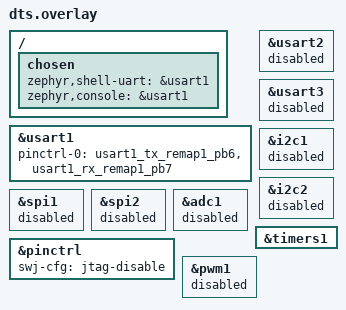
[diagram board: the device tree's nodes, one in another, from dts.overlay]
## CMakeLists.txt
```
# SPDX-License-Identifier: GPL-2.0-or-later
cmake_minimum_required(VERSION 3.20.1)
set(BOARD stm32_min_dev_blue)
set(DTC_OVERLAY_FILE dts.overlay)
find_package(Zephyr REQUIRED)
project(keypecker VERSION 1)
target_sources(
	app PRIVATE
	src/kp.c
	src/kp_shell.c
	src/kp_input.c
	src/kp_act.c
	src/kp_cap.c
	src/kp_sample.c
	src/kp_meas.c
	src/kp_table.c
)
```

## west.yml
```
# SPDX-License-Identifier: GPL-2.0-or-later
manifest:
  self:
    path: keypecker

  remotes:
    - name: zephyrproject-rtos
      url-base: https://github.com/zephyrproject-rtos

  projects:
    - name: zephyr
      remote: zephyrproject-rtos
      revision: main
      import: true
```

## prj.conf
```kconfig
CONFIG_ASSERT=y

CONFIG_FLASH_SIZE=128
CONFIG_PRINTK=y
CONFIG_SHELL=y
CONFIG_SHELL_HELP=y
CONFIG_SHELL_STACK_SIZE=2048
CONFIG_SHELL_BACKEND_SERIAL=y
CONFIG_SHELL_PROMPT_UART="keypecker:~$ "

CONFIG_HWINFO_SHELL=n

CONFIG_THREAD_MONITOR=y
CONFIG_INIT_STACKS=y
CONFIG_BOOT_BANNER=y
CONFIG_THREAD_NAME=y
CONFIG_LOG=y
CONFIG_LOG_MODE_MINIMAL=y
CONFIG_CBPRINTF_NANO=y
```

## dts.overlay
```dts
/*
 * Copyright (c) 2021 Nordic Semiconductor ASA
 *
 * SPDX-License-Identifier: Apache-2.0
 */

/ {
	chosen {
		zephyr,shell-uart = &usart1;
		zephyr,console = &usart1;
	};
};

&usart1 {
	status = "okay";
	pinctrl-0 = < &usart1_tx_remap1_pb6 &usart1_rx_remap1_pb7 >;
};
&usart2 {
	status = "disabled";
};
&usart3 {
	status = "disabled";
};
&i2c1 {
	status = "disabled";
};
&i2c2 {
	status = "disabled";
};
&spi1 {
	status = "disabled";
};
&spi2 {
	status = "disabled";
};
&adc1 {
	status = "disabled";
};
&pinctrl {
	swj-cfg = "jtag-disable";
};

&timers1 {
	status = "okay";
};

&pwm1 {
	status = "disabled";
};
```

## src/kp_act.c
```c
/** @file
 *  @brief Keypecker actuator
 */

/*
 * Copyright (c) 2022 Nikolai Kondrashov
 *
 * SPDX-License-Identifier: GPL-2.0-or-later
 */

#include "kp_act.h"

/*
 * Only changed upon initialization.
 */

/** The GPIO port device */
static const struct device * volatile kp_act_gpio = NULL;

/** The "disable" output GPIO pin */
static gpio_pin_t kp_act_gpio_pin_disable;

/** The "dir" output GPIO pin */
static gpio_pin_t kp_act_gpio_pin_dir;

/** The "step" output GPIO pin */
static gpio_pin_t kp_act_gpio_pin_step;

/*
 * General state changed by all functions
 */
/** The spinlock protecting the base state */
static struct k_spinlock kp_act_lock = {};

/** Execute the following statement with base state lock held */
#define KP_ACT_WITH_LOCK \
	for (k_spinlock_key_t _key = k_spin_lock(&kp_act_lock), \
			      _i = {0}; \
	     _i.key == 0; \
	     k_spin_unlock(&kp_act_lock, _key), _i.key = 1)

/** The current actuator position, in steps */
static volatile int32_t kp_act_pos;

/** True if a move has to be aborted, false otherwise */
static volatile bool kp_act_move_aborted;

/*
 * Movement state accessed by move.../locate functions
 */

/** The semaphore signaling a movement can be started */
static K_SEM_DEFINE(kp_act_move_available, 1, 1);

/** The semaphore signaling a movement should begin */
static K_SEM_DEFINE(kp_act_move_begin, 0, 1);

/** The move target position, in steps */
static int32_t kp_act_target;

/** The timestamp of the last step in cycles */
static uint32_t kp_act_move_last_cycles;

/** True if the last step was in the positive direction, false otherwise */
static bool kp_act_move_last_positive;

/** The semaphore signaling a movement is done */
static K_SEM_DEFINE(kp_act_move_done, 0, 1);

/** The move result, only valid when kp_act_move_done is available */
static volatile enum kp_act_move_rc kp_act_move_rc;

/*
 * End of state
 */

/**
 * Check if the actuator power is off, assuming the state mutex is held.
 *
 * @return True if the power is off, false if on.
 */
static inline bool
kp_act_is_off_locked(void)
{
	return gpio_pin_get(kp_act_gpio, kp_act_gpio_pin_disable);
}

/**
 * Check if the actuator power is on, assuming the state mutex is held.
 *
 * @return True if the power is on, false if off.
 */
static inline bool
kp_act_is_on_locked(void)
{
	return !kp_act_is_off_locked();
}

bool
kp_act_is_off(void)
{
	bool is_off;
	assert(kp_act_is_initialized());
	KP_ACT_WITH_LOCK {
		is_off = kp_act_is_off_locked();
	}
	return is_off;
}

bool
kp_act_on(void)
{
	bool turned_on = false;
	assert(kp_act_is_initialized());
	KP_ACT_WITH_LOCK {
		if (kp_act_is_off_locked()) {
			gpio_pin_set(kp_act_gpio, kp_act_gpio_pin_disable, 0);
			turned_on = true;
		}
	}
	return turned_on;
}

bool
kp_act_off(void)
{
	bool turned_off = false;
	assert(kp_act_is_initialized());
	KP_ACT_WITH_LOCK {
		/* If we're moving, the move aborts with KP_ACT_MOVE_RC_OFF */
		if (kp_act_is_on_locked()) {
			gpio_pin_set(kp_act_gpio, kp_act_gpio_pin_disable, 1);
			kp_act_pos = 0;
			turned_off = true;
		}
	}
	return turned_off;
}

int32_t
kp_act_locate(void)
{
	int32_t pos;
	assert(kp_act_is_initialized());
	KP_ACT_WITH_LOCK {
		pos = kp_act_is_on_locked()
			? kp_act_pos
			: KP_ACT_POS_INVALID;
	}
	return pos;
}

/** Move timer */
static K_TIMER_DEFINE(kp_act_move_timer, NULL, NULL);

/** Minimum move timer period, us */
#define KP_ACT_MOVE_TIMER_PERIOD_MIN_US	400

/** Maximum move timer period, us */
#define KP_ACT_MOVE_TIMER_PERIOD_MAX_US	4000

/**
 * Wait for next timer tick, or go to a label if timer is stopped.
 *
 * @param _stop_label	The label to go to if timer is stopped.
 */
#define KP_ACT_MOVE_TIMER_SYNC(_stop_label) \
	do {                                                    \
		/* If the timer is stopped or not started */    \
		if (!k_timer_status_sync(&kp_act_move_timer)) { \
			goto _stop_label;                       \
		}                                               \
	} while (0)

void
kp_act_move_thread_fn(void *arg1, void *arg2, void *arg3)
{
	bool positive = false;
	assert(kp_act_is_initialized());

	/* While we can get the "begin" semaphore */
	while (k_sem_take(&kp_act_move_begin, K_FOREVER) == 0) {
		/* Run the timer */
		while (true) {
			/* Control */
			KP_ACT_MOVE_TIMER_SYNC(stop);
			KP_ACT_WITH_LOCK {
				if (kp_act_is_off_locked()) {
					kp_act_move_rc = KP_ACT_MOVE_RC_OFF;
					k_timer_stop(&kp_act_move_timer);
					continue;
				}
				if (kp_act_move_aborted) {
					kp_act_move_rc =
						KP_ACT_MOVE_RC_ABORTED;
					k_timer_stop(&kp_act_move_timer);
					continue;
				}
				if (kp_act_target == kp_act_pos) {
					kp_act_move_rc = KP_ACT_MOVE_RC_OK;
					k_timer_stop(&kp_act_move_timer);
					continue;
				}
				positive = kp_act_target > kp_act_pos;
				gpio_pin_set(kp_act_gpio, kp_act_gpio_pin_dir,
					     !positive);
			}
			/* Raise */
			KP_ACT_MOVE_TIMER_SYNC(stop);
			gpio_pin_set(kp_act_gpio, kp_act_gpio_pin_step, 1);
			kp_act_move_last_cycles = k_cycle_get_32();
			kp_act_move_last_positive = positive;
			/* Hold */
			KP_ACT_MOVE_TIMER_SYNC(stop);
			KP_ACT_WITH_LOCK {
				if (positive) {
					kp_act_pos++;
				} else {
					kp_act_pos--;
				}
			}
			/* Fall */
			KP_ACT_MOVE_TIMER_SYNC(stop);
			gpio_pin_set(kp_act_gpio, kp_act_gpio_pin_step, 0);
		}
stop:;
		k_sem_give(&kp_act_move_done);
	}
}

#undef KP_ACT_MOVE_TIMER_SYNC

/** The thread moving the actuator */
K_THREAD_DEFINE(kp_act_move_thread, 512,
		kp_act_move_thread_fn, NULL, NULL, NULL,
		-1, 0, -1);

void
kp_act_start_move(bool relative, int32_t steps, uint32_t speed)
{
	bool started = false;
	uint32_t period_us;
	k_timeout_t delay = K_NO_WAIT;
	assert(relative || kp_act_pos_is_valid(steps));
	assert(speed <= 100);
	assert(kp_act_is_initialized());

	/* Wait for a move to be available */
	k_sem_take(&kp_act_move_available, K_FOREVER);

	/* Start the timer */
	KP_ACT_WITH_LOCK {
		/* If we have the power off */
		if (kp_act_is_off_locked()) {
			kp_act_move_rc = KP_ACT_MOVE_RC_OFF;
			continue;
		}
		/* Calculate target steps */
		kp_act_target =
			relative ? kp_act_pos + steps : steps;
		/* If we don't have to move */
		if (kp_act_target == kp_act_pos) {
			kp_act_move_rc = KP_ACT_MOVE_RC_OK;
			continue;
		}

		kp_act_move_aborted = false;

		/* If our direction is different from the last step */
		if ((kp_act_target > kp_act_pos) !=
				kp_act_move_last_positive) {
			/*
			 * Minimum turn delay, microseconds.
			 * The faster we move, the more time we need to absorb
			 * the momentum.
			 */
			uint32_t turn_delay_us =
				(KP_ACT_MOVE_TIMER_PERIOD_MIN_US +
				 ((KP_ACT_MOVE_TIMER_PERIOD_MAX_US -
				   KP_ACT_MOVE_TIMER_PERIOD_MIN_US) *
				  speed) / 100) * 2;
			/* Current time, cycles */
			uint32_t now_cycles = k_cycle_get_32();
			/* Microseconds from the last step */
			uint32_t elapsed_us = k_cyc_to_us_floor32(
				now_cycles > kp_act_move_last_cycles
					? now_cycles - kp_act_move_last_cycles
					/* Just always wait on overflow */
					: 0
			);
			if (elapsed_us < turn_delay_us) {
				/* Wait to absorb momentum before turning */
				delay = K_USEC(turn_delay_us - elapsed_us);
			}
		}

		/* Shorter period for faster movement */
		period_us = KP_ACT_MOVE_TIMER_PERIOD_MAX_US -
			((KP_ACT_MOVE_TIMER_PERIOD_MAX_US -
			  KP_ACT_MOVE_TIMER_PERIOD_MIN_US) *
			 speed) / 100;

		k_timer_start(&kp_act_move_timer, delay, K_USEC(period_us));
		started = true;
	}

	if (started) {
		/* Begin the move */
		k_sem_give(&kp_act_move_begin);
	} else {
		/* Complete the move */
		k_sem_give(&kp_act_move_done);
	}
}

void
kp_act_finish_move_event_init(struct k_poll_event *event)
{
	assert(kp_act_is_initialized());
	k_poll_event_init(event, K_POLL_TYPE_SEM_AVAILABLE,
			  K_POLL_MODE_NOTIFY_ONLY, &kp_act_move_done);
}

enum kp_act_move_rc
kp_act_finish_move(k_timeout_t timeout)
{
	enum kp_act_move_rc rc;
	assert(kp_act_is_initialized());

	/* Wait for the move to finish */
	if (k_sem_take(&kp_act_move_done, timeout)) {
		return KP_ACT_MOVE_TIMEOUT;
	}

	/* Remember the result */
	rc = kp_act_move_rc;

	/* Mark next move as available */
	k_sem_give(&kp_act_move_available);

	/* Return the remembered result */
	return rc;
}

bool
kp_act_abort(void)
{
	bool aborted = false;
	assert(kp_act_is_initialized());
	KP_ACT_WITH_LOCK {
		if (kp_act_is_off_locked()) {
			continue;
		}
		kp_act_move_aborted = true;
		aborted = true;
	}
	return aborted;
}

bool
kp_act_is_initialized(void)
{
	return kp_act_gpio != NULL;
}

void
kp_act_init(const struct device *gpio,
		gpio_pin_t disable_pin,
		gpio_pin_t dir_pin,
		gpio_pin_t step_pin)
{
	assert(gpio != NULL);
	assert(device_is_ready(gpio));
	assert(!kp_act_is_initialized());

	/* Move state */
	kp_act_target = 0;
	kp_act_move_last_cycles = 0;
	kp_act_move_last_positive = false;

	/* General state */
	kp_act_pos = 0;
	kp_act_move_aborted = false;

	/* Init state */
	kp_act_gpio_pin_disable = disable_pin;
	kp_act_gpio_pin_dir = dir_pin;
	kp_act_gpio_pin_step = step_pin;
	gpio_pin_configure(gpio, kp_act_gpio_pin_disable,
				GPIO_OPEN_DRAIN | GPIO_OUTPUT_HIGH);
	gpio_pin_configure(gpio, kp_act_gpio_pin_dir,
				GPIO_PUSH_PULL | GPIO_OUTPUT_LOW);
	gpio_pin_configure(gpio, kp_act_gpio_pin_step,
				GPIO_PUSH_PULL | GPIO_OUTPUT_LOW);

	/* Mark actuator initialized */
	kp_act_gpio = gpio;

	/* Start the actuator-moving thread */
	k_thread_start(kp_act_move_thread);

	assert(kp_act_is_initialized());
}
```

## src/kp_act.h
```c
/** @file
 *  @brief Keypecker actuator
 */

/*
 * Copyright (c) 2022 Nikolai Kondrashov
 *
 * SPDX-License-Identifier: GPL-2.0-or-later
 */

#ifndef KP_ACT_H_
#define KP_ACT_H_

#include <zephyr/drivers/gpio.h>
#include <zephyr/kernel.h>
#include <stdbool.h>
#include <assert.h>

#ifdef __cplusplus
extern "C" {
#endif

/**
 * Initialize the actuator to a powered-off state.
 *
 * @param gpio		The device for the GPIO port to use to control the
 *			actuator.
 * @param disable_pin	The disable pin number on the GPIO port.
 * @param dir_pin	The dir pin number on the GPIO port.
 * @param step_pin	The step pin number on the GPIO port.
 */
extern void kp_act_init(const struct device *gpio,
			gpio_pin_t disable_pin,
			gpio_pin_t dir_pin,
			gpio_pin_t step_pin);

/**
 * Check if the actuator is initialized.
 *
 * @return True if the actuator is initialized, false if not.
 */
extern bool kp_act_is_initialized(void);

/**
 * Check if the actuator power is off.
 *
 * @return True if the power is off, false if on.
 */
extern bool kp_act_is_off(void);

/**
 * Check if the actuator power is on.
 *
 * @return True if the power is on, false if off.
 */
static inline bool
kp_act_is_on(void)
{
	assert(kp_act_is_initialized());
	return !kp_act_is_off();
}

/**
 * Turn the actuator power on, if not on already.
 *
 * @return True if the power was turned on, false if it was already on.
 */
extern bool kp_act_on(void);

/**
 * Turn the actuator power off.
 *
 * @return True if the power turned off, false if it was already off.
 */
extern bool kp_act_off(void);

/** Invalid (unavailable) actuator position */
#define KP_ACT_POS_INVALID	INT32_MIN

/** Minimum possible actuator position */
#define KP_ACT_POS_MIN		(INT32_MIN + 1)

/** Maximum possible actuator position */
#define KP_ACT_POS_MAX		INT32_MAX

/**
 * Check if a position is valid.
 *
 * @param pos	The position to check.
 *
 * @return True if the position is valid, false otherwise.
 */
static inline bool kp_act_pos_is_valid(int32_t pos)
{
	return pos != KP_ACT_POS_INVALID;
}

/**
 * Retrieve the absolute position of a powered actuator.
 *
 * @return The position, if successful, or KP_ACT_POS_INVALID, if the actuator
 * 	   is powered off.
 */
extern int32_t kp_act_locate(void);

/** Result code of a movement attempt */
enum kp_act_move_rc {
	/** Move succeeded / finished */
	KP_ACT_MOVE_RC_OK,
	/** Move is aborted */
	KP_ACT_MOVE_RC_ABORTED,
	/** Actuator is off (power is invalid) */
	KP_ACT_MOVE_RC_OFF,
	/** Waiting for a move to finish timed out */
	KP_ACT_MOVE_TIMEOUT,
};

/**
 * Start moving the actuator.
 *
 * @param relative	True if the move is relative, false if absolute.
 * @param steps		The number of steps to move by, if "relative" is true.
 * 			The absolute position, in steps, if "relative" is
 * 			false. Positive - lower, negative - higher.
 * @param speed		The speed with which to move, 0-100%.
 */
extern void kp_act_start_move(bool relative, int32_t steps, uint32_t speed);

/**
 * Finish moving the actuator.
 *
 * @param timeout	The time to wait for the move to finish, or one of
 * 			the special values K_NO_WAIT and K_FOREVER.
 *
 * @return The move result code.
 */
extern enum kp_act_move_rc kp_act_finish_move(k_timeout_t timeout);

/**
 * Initialize a poll event to wait for finished actuator moves.
 *
 * @param event	The poll event to initialize.
 */
extern void kp_act_finish_move_event_init(struct k_poll_event *event);

/**
 * Move the actuator.
 *
 * @param relative	True if the move is relative, false if absolute.
 * @param steps		The number of steps to move by, if "relative" is true.
 * 			The absolute position, in steps, if "relative" is
 * 			false. Positive - lower, negative - higher.
 * @param speed		The speed with which to move, 0-100%.
 *
 * @return The move result code.
 */
static inline enum kp_act_move_rc kp_act_move(bool relative,
					      int32_t steps,
					      uint32_t speed)
{
	assert(relative || kp_act_pos_is_valid(steps));
	assert(speed <= 100);
	assert(kp_act_is_initialized());
	kp_act_start_move(relative, steps, speed);
	return kp_act_finish_move(K_FOREVER);
}

/**
 * Move the actuator to an absolute position.
 * Waits for the previous move to be finished/aborted.
 *
 * @param pos	The absolute position to move the actuator to (must be valid).
 * @param speed	The speed with which to move, 0-100%.
 *
 * @return The movement result.
 */
static inline enum kp_act_move_rc
kp_act_move_to(int32_t pos, uint32_t speed)
{
	assert(kp_act_pos_is_valid(pos));
	assert(speed <= 100);
	assert(kp_act_is_initialized());
	return kp_act_move(false, pos, speed);
}

/**
 * Start moving the actuator to an absolute position.
 * Waits for the previous move to be finished/aborted.
 *
 * @param pos	The absolute position to move the actuator to (must be valid).
 * @param speed	The speed with which to move, 0-100%.
 */
static inline void
kp_act_start_move_to(int32_t pos, uint32_t speed)
{
	assert(kp_act_pos_is_valid(pos));
	assert(speed <= 100);
	assert(kp_act_is_initialized());
	kp_act_start_move(false, pos, speed);
}

/**
 * Move the actuator by a specified number of steps.
 *
 * @param steps	The number of steps to move by: positive values
 * 		- lower, negative - higher.
 * @param speed	The speed with which to move, 0-100%.
 *
 * @return The movement result.
 */
static inline enum kp_act_move_rc
kp_act_move_by(int32_t steps, uint32_t speed)
{
	assert(speed <= 100);
	assert(kp_act_is_initialized());
	return kp_act_move(true, steps, speed);
}

/**
 * Start moving the actuator by a specified number of steps.
 *
 * @param steps	The number of steps to move by: positive values
 * 		- lower, negative - higher.
 * @param speed	The speed with which to move, 0-100%.
 *
 * @return The movement result.
 */
static inline void
kp_act_start_move_by(int32_t steps, uint32_t speed)
{
	assert(speed <= 100);
	assert(kp_act_is_initialized());
	kp_act_start_move(true, steps, speed);
}

/**
 * Abort the actuator's movement in progress, if any.
 *
 * @return True if there was no movement or it was aborted,
 * 	   false if the actuator was not powered.
 */
extern bool kp_act_abort(void);

#ifdef __cplusplus
}
#endif

#endif /* KP_ACT_H_ */
```

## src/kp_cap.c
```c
/** @file
 *  @brief Keypecker capturer
 */

/*
 * Copyright (c) 2022 Nikolai Kondrashov
 *
 * SPDX-License-Identifier: GPL-2.0-or-later
 */

#include "kp_cap.h"
#include "kp_misc.h"
#include <string.h>

/** Masks for the channels available for capture */
static const uint32_t kp_cap_ch_mask_list[KP_CAP_CH_NUM] = {
	LL_TIM_CHANNEL_CH2,
	LL_TIM_CHANNEL_CH3,
};

/** Capture interrupt-enabling/interrupt-flag masks for each channel */
/* NOTE: Assuming SR bits match DIER bits */
static const uint32_t kp_cap_ch_ccif_mask_list[KP_CAP_CH_NUM] = {
	TIM_SR_CC2IF,
	TIM_SR_CC3IF,
};

/** Overcapture flag masks for each channel */
static const uint32_t kp_cap_ch_ccof_mask_list[KP_CAP_CH_NUM] = {
	TIM_SR_CC2OF,
	TIM_SR_CC3OF,
};

/** Offset of the captured-value register for each channel, bytes */
static const size_t kp_cap_ch_ccr_offset_list[KP_CAP_CH_NUM] = {
	offsetof(TIM_TypeDef, CCR2),
	offsetof(TIM_TypeDef, CCR3),
};

/** The timer to use for capture */
static TIM_TypeDef* kp_cap_timer = NULL;

/** Debugg output configuration */
struct kp_cap_dbg_conf kp_cap_dbg_conf;

/** The semaphore signaling a capture can be started */
static K_SEM_DEFINE(kp_cap_available, 1, 1);

/** The capture interrupt mask for all channels to be captured */
static uint32_t kp_cap_ch_ccif_mask;

/** The maximum number of ticks to await capture of all channels */
static uint32_t kp_cap_timeout_ticks;

/** The minimum number of ticks to wait for a channel to bounce */
static uint32_t kp_cap_bounce_ticks;

/** The capture abort flag */
static volatile bool kp_cap_aborted;

/** The semaphore signaling a capture is done */
static K_SEM_DEFINE(kp_cap_done, 0, 1);

/** The interrupt state spinlock */
/** Only needs to be held if kp_cap_available is taken */
static struct k_spinlock kp_cap_lock = {};

void
kp_cap_isr(void *arg)
{
	static const struct kp_cap_dbg_conf *dbg = &kp_cap_dbg_conf;
	bool done = false;
	k_spinlock_key_t key;
	size_t i;

	assert(kp_cap_is_initialized());

	key = k_spin_lock(&kp_cap_lock);

	/* If the capture is not aborted */
	if (!kp_cap_aborted) {
		uint32_t sr = kp_cap_timer->SR;
		uint32_t masked_sr = sr & kp_cap_timer->DIER;
		/* If the timer got triggered */
		if (masked_sr & TIM_SR_TIF) {
			/* Raise the debugging pins, if any */
			if (dbg->gpio && dbg->update_pin != UINT8_MAX) {
				gpio_pin_set(dbg->gpio, dbg->update_pin, 1);
			}
			for (i = 0; dbg->gpio && i < KP_CAP_CH_NUM; i++) {
				if (dbg->cap_pin_list[i] != UINT8_MAX) {
					gpio_pin_set(
						dbg->gpio,
						dbg->cap_pin_list[i],
						1
					);
				}
			}
			/* Clear the interrupt flag */
			kp_cap_timer->DIER &= ~TIM_SR_TIF;
			kp_cap_timer->SR &= ~TIM_SR_TIF;
		/* Else, If both the capture and bounce times have expired */
		} else if (masked_sr & TIM_SR_UIF) {
			/* Disable the trigger */
			LL_TIM_SetSlaveMode(kp_cap_timer,
						LL_TIM_SLAVEMODE_DISABLED);
			/* Stop the timer */
			LL_TIM_DisableCounter(kp_cap_timer);
			/* Disable all the interrupts */
			kp_cap_timer->DIER = 0;
			/* Lower the debugging pin, if any */
			if (dbg->gpio && dbg->update_pin != UINT8_MAX) {
				gpio_pin_set(dbg->gpio, dbg->update_pin, 0);
			}
			/* Prepare to signal the capture is done */
			done = true;
		} else {
			uint32_t ccif_mask = sr & kp_cap_ch_ccif_mask;
			uint32_t new_ccif_mask = ccif_mask & kp_cap_timer->DIER;

			/* Lower debugging GPIO pins, if specified */
			for (i = 0; dbg->gpio && i < KP_CAP_CH_NUM; i++) {
				if (dbg->cap_pin_list[i] != UINT8_MAX &&
				    (kp_cap_ch_ccif_mask_list[i] &
				     new_ccif_mask)) {
					gpio_pin_set(
						dbg->gpio,
						dbg->cap_pin_list[i],
						0
					);
				}
			}

			/* If all channels were captured (but may bounce) */
			if (ccif_mask == kp_cap_ch_ccif_mask) {
				/* Shorten the capture, if possible */
				LL_TIM_DisableCounter(kp_cap_timer);
				if ((uint32_t)kp_cap_timer->CNT <
						kp_cap_timeout_ticks) {
					LL_TIM_SetAutoReload(
						kp_cap_timer,
						kp_cap_timer->CNT +
						kp_cap_bounce_ticks
					);
				}
				LL_TIM_EnableCounter(kp_cap_timer);
			}

			/* Disable the interrupts we've processed */
			kp_cap_timer->DIER &= ~ccif_mask;
		}
	}

	k_spin_unlock(&kp_cap_lock, key);

	if (done) {
		/* Signal the capture is done */
		k_sem_give(&kp_cap_done);
	}
}

size_t
kp_cap_conf_ch_num(const struct kp_cap_conf *conf, enum kp_cap_dirs dirs)
{
	size_t i;
	size_t dir_ch_num;
	assert(kp_cap_conf_is_valid(conf));
	assert(kp_cap_dirs_is_valid(dirs));
	for (dir_ch_num = 0, i = 0; i < ARRAY_SIZE(conf->ch_list); i++) {
		if (conf->ch_list[i].dirs & dirs) {
			dir_ch_num++;
		}
	}
	return dir_ch_num;
}

size_t
kp_cap_conf_ch_res_idx(const struct kp_cap_conf *conf, bool even_down,
		       size_t pass, size_t ch)
{
	const bool odd_pass = pass & 1;
	/* Number of channel results per round (two passes) */
	size_t round_ch_res_num = 0;
	/* Channel result index in this pass */
	size_t pass_ch_res_idx = 0;
	size_t i;

	assert(kp_cap_conf_is_valid(conf));
	assert((even_down & 1) == even_down);
	assert(ch < ARRAY_SIZE(conf->ch_list));

	for (i = 0; i < ARRAY_SIZE(conf->ch_list); i++) {
		enum kp_cap_dirs dirs = conf->ch_list[i].dirs;

		if (dirs & KP_CAP_DIRS_UP) {
			round_ch_res_num++;
		}
		if (dirs & KP_CAP_DIRS_DOWN) {
			round_ch_res_num++;
		}
		/* If this is an odd pass */
		if (odd_pass) {
			/*
			 * If the channel is enabled in the previous
			 * (even) pass
			 */
			if (dirs & kp_cap_dirs_from_down(even_down)) {
				pass_ch_res_idx++;
			}
		}
		/* If the channel is enabled in this pass */
		if (i < ch &&
		    (dirs & kp_cap_dirs_from_down(even_down ^ odd_pass))) {
			pass_ch_res_idx++;
		}
	}
	return round_ch_res_num * (pass >> 1) + pass_ch_res_idx;
}

void
kp_cap_start(const struct kp_cap_conf *conf, enum kp_cap_dirs dirs)
{
	size_t i;
	const struct kp_cap_ch_conf *ch_conf;
	uint32_t ch_mask;
	k_spinlock_key_t key;

	assert(kp_cap_is_initialized());
	assert(kp_cap_conf_is_valid(conf));
	assert(kp_cap_dirs_is_valid(dirs));

	/* Wait for the capture to be available */
	k_sem_take(&kp_cap_available, K_FOREVER);

	/* Lock the interrupt state */
	key = k_spin_lock(&kp_cap_lock);

	/* Initialize the capture configuration */
	kp_cap_ch_ccif_mask = 0;

	/* For each channel */
	for (i = 0; i < KP_CAP_CH_NUM; i++) {
		ch_mask = kp_cap_ch_mask_list[i];
		/* NOTE: Must be considered invalid before the check below */
		ch_conf = &conf->ch_list[i];
		/* If the channel's capture is enabled */
		if (ch_conf->dirs & dirs) {
			/* Configure and enable the capture */
			kp_cap_ch_ccif_mask |= kp_cap_ch_ccif_mask_list[i];
			LL_TIM_IC_Config(
				kp_cap_timer, ch_mask,
				LL_TIM_ACTIVEINPUT_DIRECTTI |
				LL_TIM_ICPSC_DIV1 |
				LL_TIM_IC_FILTER_FDIV1 |
				(ch_conf->rising
					? LL_TIM_IC_POLARITY_RISING
					: LL_TIM_IC_POLARITY_FALLING)
			);
			LL_TIM_CC_EnableChannel(kp_cap_timer, ch_mask);
		} else {
			/* Disable the capture */
			LL_TIM_CC_DisableChannel(kp_cap_timer, ch_mask);
		}
	}

	/* Reset abort flag */
	kp_cap_aborted = false;

	/* Remember the number of ticks to wait for capture */
	kp_cap_timeout_ticks = conf->timeout_us / KP_CAP_RES_US;

	/* Remember the number of ticks to wait for a channel to bounce */
	kp_cap_bounce_ticks = conf->bounce_us / KP_CAP_RES_US;

	/* Clear all the overcapture/interrupt flags */
	kp_cap_timer->SR = 0;

	/* Enable only the interrupts we need */
	/* NOTE: Assuming SR bits match DIER bits */
	kp_cap_timer->DIER = TIM_SR_TIF | kp_cap_ch_ccif_mask | TIM_SR_UIF;

	/* Set auto-reload register to the total timeout */
	LL_TIM_SetAutoReload(kp_cap_timer,
			     kp_cap_timeout_ticks +
			     kp_cap_bounce_ticks);

	/* Setup the trigger to start (but not stop) counting */
	LL_TIM_SetSlaveMode(kp_cap_timer, LL_TIM_SLAVEMODE_TRIGGER);

	/* Unlock the interrupt state */
	k_spin_unlock(&kp_cap_lock, key);
}

bool
kp_cap_abort(void)
{
	bool aborted;
	k_spinlock_key_t key;

	assert(kp_cap_is_initialized());

	/* Lock the interrupt state */
	key = k_spin_lock(&kp_cap_lock);

	/* If the timer is primed for triggering, i.e. we're capturing */
	if ((kp_cap_timer->SMCR & TIM_SMCR_SMS) == LL_TIM_SLAVEMODE_TRIGGER) {
		/* Disable the trigger */
		LL_TIM_SetSlaveMode(kp_cap_timer, LL_TIM_SLAVEMODE_DISABLED);
		/* Stop the timer */
		LL_TIM_DisableCounter(kp_cap_timer);
		/* Disable all the interrupts */
		kp_cap_timer->DIER = 0;
		/* Mark capture as aborted */
		kp_cap_aborted = true;
		/* Report as aborted */
		aborted = true;
	} else {
		/* Report as not aborted */
		aborted = false;
	}

	/* Unlock the interrupt state */
	k_spin_unlock(&kp_cap_lock, key);

	if (aborted) {
		/* Signal the capture is done */
		k_sem_give(&kp_cap_done);
	}

	return aborted;
}

void
kp_cap_finish_event_init(struct k_poll_event *event)
{
	assert(kp_cap_is_initialized());
	k_poll_event_init(event, K_POLL_TYPE_SEM_AVAILABLE,
			  K_POLL_MODE_NOTIFY_ONLY, &kp_cap_done);
}

enum kp_cap_rc
kp_cap_finish(struct kp_cap_ch_res *ch_res_list,
	      size_t ch_res_num, k_timeout_t timeout)
{
	size_t i;
	struct kp_cap_ch_res *ch_res;
	enum kp_cap_ch_status status;
	uint32_t value_ticks;
	uint32_t value_us;

	assert(kp_cap_is_initialized());
	assert(ch_res_list != NULL || ch_res_num == 0);

	/* Wait for the capture to be done */
	if (k_sem_take(&kp_cap_done, timeout)) {
		return KP_CAP_RC_TIMEOUT;
	}

	/* If the capture was aborted */
	if (kp_cap_aborted) {
		/* Allow another capture */
		k_sem_give(&kp_cap_available);
		return KP_CAP_RC_ABORTED;
	}

	/* Initialize results to all timed out */
	memset(ch_res_list, 0, sizeof(*ch_res_list) * ch_res_num);

	/* For each channel */
	for (ch_res = ch_res_list, i = 0; i < KP_CAP_CH_NUM; i++) {
		/* Skip disabled channels */
		if (!LL_TIM_CC_IsEnabledChannel(kp_cap_timer,
						kp_cap_ch_mask_list[i])) {
			continue;
		}

		/* If the channel was captured */
		if (kp_cap_timer->SR & kp_cap_ch_ccif_mask_list[i]) {
			/* Read the value (clears the capture flag) */
			value_ticks = *(uint32_t *)(
				(uint8_t *)kp_cap_timer +
				kp_cap_ch_ccr_offset_list[i]
			);
			value_us = value_ticks * KP_CAP_RES_US;
			/* If the channel was over-captured */
			if (kp_cap_timer->SR & kp_cap_ch_ccof_mask_list[i]) {
				status = KP_CAP_CH_STATUS_OVERCAPTURE;
				/* Reset the overcapture flag */
				kp_cap_timer->SR &=
					~kp_cap_ch_ccof_mask_list[i];
			/* Else, if the channel was captured late */
			} else if (value_ticks > kp_cap_timeout_ticks) {
				status = KP_CAP_CH_STATUS_TIMEOUT;
			} else {
				status = KP_CAP_CH_STATUS_OK;
			}
		/* Else, channel capture has timed out */
		} else {
			status = KP_CAP_CH_STATUS_TIMEOUT;
			value_us = UINT32_MAX;
		}

		/* Output channel result, if requested */
		if (ch_res_num > 0) {
			ch_res->status = status;
			ch_res->value_us = value_us;
			ch_res_num--;
			ch_res++;
		}
	}

	/* Allow another capture */
	k_sem_give(&kp_cap_available);

	return KP_CAP_RC_OK;
}

bool
kp_cap_dirs_from_str(const char *str, enum kp_cap_dirs *pdirs)
{
	enum kp_cap_dirs dirs;
	assert(str != NULL);

	if (kp_strcasecmp(str, "none") == 0) {
		dirs = KP_CAP_DIRS_NONE;
	} else if (kp_strcasecmp(str, "up") == 0) {
		dirs = KP_CAP_DIRS_UP;
	} else if (kp_strcasecmp(str, "down") == 0) {
		dirs = KP_CAP_DIRS_DOWN;
	} else if (kp_strcasecmp(str, "both") == 0) {
		dirs = KP_CAP_DIRS_BOTH;
	} else {
		return false;
	}

	if (pdirs != NULL) {
		*pdirs = dirs;
	}

	return true;
}

const char *
kp_cap_dirs_to_lcstr(enum kp_cap_dirs dirs)
{
	static const char *str_list[] = {
#define STATUS(_token, _lc_token) [KP_CAP_DIRS_##_token] = #_lc_token
		STATUS(NONE, none),
		STATUS(UP, up),
		STATUS(DOWN, down),
		STATUS(BOTH, both),
#undef STATUS
	};
	const char *str = (dirs >= 0 && dirs < ARRAY_SIZE(str_list))
		? str_list[dirs] : NULL;
	return str == NULL ? "unknown" : str;
}

const char *
kp_cap_dirs_to_cpstr(enum kp_cap_dirs dirs)
{
	static const char *str_list[] = {
#define STATUS(_token, _cp_token) [KP_CAP_DIRS_##_token] = #_cp_token
		STATUS(NONE, None),
		STATUS(UP, Up),
		STATUS(DOWN, Down),
		STATUS(BOTH, Both),
#undef STATUS
	};
	const char *str = (dirs >= 0 && dirs < ARRAY_SIZE(str_list))
		? str_list[dirs] : NULL;
	return str == NULL ? "unknown" : str;
}

const char *
kp_cap_ch_status_to_str(enum kp_cap_ch_status status)
{
	static const char *str_list[KP_CAP_CH_STATUS_NUM] = {
#define STATUS_STR(_token) [KP_CAP_CH_STATUS_##_token] = #_token
		STATUS_STR(TIMEOUT),
		STATUS_STR(OK),
		STATUS_STR(OVERCAPTURE),
#undef STATUS_STR
	};
	const char *str = (status >= 0 && status < ARRAY_SIZE(str_list))
		? str_list[status] : NULL;
	return str == NULL ? "UNKNOWN" : str;
}

const char *
kp_cap_rc_to_str(enum kp_cap_rc rc)
{
	static const char *str_list[KP_CAP_RC_NUM] = {
#define RC_STR(_token) [KP_CAP_RC_##_token] = #_token
		RC_STR(OK),
		RC_STR(ABORTED),
		RC_STR(TIMEOUT),
#undef RC_STR
	};
	const char *str = (rc >= 0 && rc < ARRAY_SIZE(str_list))
		? str_list[rc] : NULL;
	return str == NULL ? "UNKNOWN" : str;
}

bool
kp_cap_is_initialized(void)
{
	return kp_cap_timer != NULL;
}

void
kp_cap_init(TIM_TypeDef* timer, const struct kp_cap_dbg_conf *dbg_conf)
{
	assert(!kp_cap_is_initialized());
	assert(timer != NULL);

	/* Remember the timer we're using */
	kp_cap_timer = timer;

	/* Remember debug output configuration */
	if (dbg_conf == NULL) {
		kp_cap_dbg_conf.gpio = NULL;
	} else {
		memcpy(&kp_cap_dbg_conf, dbg_conf, sizeof(kp_cap_dbg_conf));
	}

	/* Set update interrupt generation for overflow/underflow only */
	LL_TIM_SetUpdateSource(kp_cap_timer, LL_TIM_UPDATESOURCE_COUNTER);
	/* Setup prescaling to get our resolution with the system clock */
	LL_TIM_SetPrescaler(kp_cap_timer, k_us_to_cyc_floor32(KP_CAP_RES_US));
	/* Update prescaler */
	LL_TIM_GenerateEvent_UPDATE(kp_cap_timer);
	/* Count up from zero */
	LL_TIM_SetCounterMode(kp_cap_timer, LL_TIM_COUNTERMODE_UP);
	/* Disable auto-reload register preloading */
	LL_TIM_DisableARRPreload(kp_cap_timer);
	/* Configure trigger channel as input:
	 * directly connected to its input line,
	 * no prescaling (not used for triggering anyway),
	 * no filtering,
	 * rising edge detection
	 */
	LL_TIM_IC_Config(kp_cap_timer, LL_TIM_CHANNEL_CH1,
			 LL_TIM_ACTIVEINPUT_DIRECTTI |
			 LL_TIM_ICPSC_DIV1 |
			 LL_TIM_IC_FILTER_FDIV1 |
			 LL_TIM_IC_POLARITY_RISING);
	/* Set filtered and polarity-configured channel as trigger */
	LL_TIM_SetTriggerInput(kp_cap_timer, LL_TIM_TS_TI1FP1);
	/* Setup trigger to start (but not stop) counting */
	LL_TIM_SetSlaveMode(kp_cap_timer, LL_TIM_SLAVEMODE_TRIGGER);

	assert(kp_cap_is_initialized());
}
```

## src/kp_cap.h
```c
/** @file
 *  @brief Keypecker capturer
 */

/*
 * Copyright (c) 2022 Nikolai Kondrashov
 *
 * SPDX-License-Identifier: GPL-2.0-or-later
 */

#ifndef KP_CAP_H_
#define KP_CAP_H_

#include <zephyr/drivers/gpio.h>
#include <zephyr/kernel.h>
#include <stm32_ll_tim.h>
#include <stdbool.h>
#include <assert.h>

#ifdef __cplusplus
extern "C" {
#endif

/** Timer resolution, microseconds */
#define KP_CAP_RES_US	20

/** Maximum time capture of all selected channels can take, us */
#define KP_CAP_TIME_MAX_US	((uint32_t)KP_CAP_RES_US * UINT16_MAX)

/** Number of decimal digits in the maximum capture time, us */
#define KP_CAP_TIME_MAX_DIGITS	7

/** Number of available capture channels */
#define KP_CAP_CH_NUM	2

/** Maximum number of characters in a user's channel name */
#define KP_CAP_CH_NAME_MAX_LEN	15

/** Capture direction sets (bitmaps) */
enum kp_cap_dirs {
	/** No directions (the empty set) */
	KP_CAP_DIRS_NONE	= 0,
	/** Up (a unit set) */
	KP_CAP_DIRS_UP,
	/** Down (a unit set) */
	KP_CAP_DIRS_DOWN,
	/** Both up and down (the universal set) */
	KP_CAP_DIRS_BOTH
};

/** Non-empty capture direction set index */
enum kp_cap_ne_dirs {
	/** Up */
	KP_CAP_NE_DIRS_UP = 0,
	/** Down */
	KP_CAP_NE_DIRS_DOWN,
	/** Both up and down */
	KP_CAP_NE_DIRS_BOTH,
	/** Number of non-empty direction sets (not an index itself) */
	KP_CAP_NE_DIRS_NUM
};

/**
 * Check if a capture direction set is valid.
 *
 * @param dirs	The direction set to check.
 *
 * @return True if the direction set is valid, false otherwise.
 */
static inline bool
kp_cap_dirs_is_valid(enum kp_cap_dirs dirs)
{
	return (dirs & ~KP_CAP_DIRS_BOTH) == 0;
}

/**
 * Check that a capture direction set is a unit set.
 * That is, it contains exactly one member (either UP or DOWN).
 *
 * @param dirs	The direction set to check.
 *
 * @return True if the set is either UP or DOWN.
 */
static bool kp_cap_dirs_is_unit(enum kp_cap_dirs dirs)
{
	assert(kp_cap_dirs_is_valid(dirs));
	return dirs == KP_CAP_DIRS_UP || dirs == KP_CAP_DIRS_DOWN;
}

/**
 * Produce a unit capture direction set from a boolean direction,
 * meaning "down" when true.
 *
 * @param down	True if the direction is down, false if up.
 *
 * @return The generated direction set.
 */
static inline enum kp_cap_dirs kp_cap_dirs_from_down(bool down)
{
	assert((down & 1) == down);
	return KP_CAP_DIRS_UP + down;
}

/**
 * Convert a unit capture direction set to a boolean direction,
 * meaning "down" when true.
 *
 * @param dirs	The unit direction set to convert.
 *
 * @return True if the direction was down, and false if up.
 */
static inline bool kp_cap_dirs_to_down(enum kp_cap_dirs dirs)
{
	assert(kp_cap_dirs_is_unit(dirs));
	return dirs - KP_CAP_DIRS_UP;
}

/**
 * Produce a unit capture direction set from a boolean direction,
 * meaning "up" when true.
 *
 * @param up	True if the direction is up, false if down.
 *
 * @return The generated direction set.
 */
static inline enum kp_cap_dirs kp_cap_dirs_from_up(bool up)
{
	assert((up & 1) == up);
	return KP_CAP_DIRS_DOWN - up;
}

/**
 * Convert a unit capture direction set to a boolean direction,
 * meaning "up" when true.
 *
 * @param dirs	The unit direction set to convert.
 *
 * @return True if the direction was up, and false if down.
 */
static inline bool kp_cap_dirs_to_up(enum kp_cap_dirs dirs)
{
	assert(kp_cap_dirs_is_unit(dirs));
	return KP_CAP_DIRS_DOWN - dirs;
}

/**
 * Convert a direction set to an index of a non-empty direction set.
 *
 * @param dirs	The direction set to convert. Must be a non-empty set.
 *
 * @return The index of the non-empty direction set.
 */
static inline enum kp_cap_ne_dirs kp_cap_dirs_to_ne(enum kp_cap_dirs dirs)
{
	assert(kp_cap_dirs_is_valid(dirs));
	assert(dirs != KP_CAP_DIRS_NONE);
	return (enum kp_cap_ne_dirs)(dirs - 1);
}

/**
 * Convert a non-empty direction set index to a direction set.
 *
 * @param ne_dirs	The index to produce a direction set from.
 *
 * @return The non-empty direction set corresponding to the index.
 */
static inline enum kp_cap_dirs kp_cap_dirs_from_ne(enum kp_cap_ne_dirs ne_dirs)
{
	assert(ne_dirs < KP_CAP_NE_DIRS_NUM);
	return (enum kp_cap_dirs)(ne_dirs + 1);
}

/**
 * Produce the index of a unit capture direction set from a boolean direction,
 * meaning "down" when true.
 *
 * @param down	True if the direction is down, false if up.
 *
 * @return The generated direction set index.
 */
static inline enum kp_cap_ne_dirs kp_cap_ne_dirs_from_down(bool down)
{
	assert((down & 1) == down);
	return (enum kp_cap_ne_dirs)down;
}

/**
 * Produce the index of a unit capture direction set from a boolean direction,
 * meaning "up" when true.
 *
 * @param up	True if the direction is up, false if down.
 *
 * @return The generated direction set index.
 */
static inline enum kp_cap_ne_dirs kp_cap_ne_dirs_from_up(bool up)
{
	assert((up & 1) == up);
	return (enum kp_cap_ne_dirs)(KP_CAP_NE_DIRS_DOWN - up);
}

/**
 * Convert a string to a capture direction set (regardless of case).
 *
 * @param str	The string to convert.
 * @param pdirs	Location for the converted direction set (if valid).
 * 		Can be NULL to discard the converted direction set.
 *
 * @return True if the string was valid and the direction set was output,
 *         False, if the string was invalid and the direction set was not
 *         output.
 */
extern bool kp_cap_dirs_from_str(const char *str, enum kp_cap_dirs *pdirs);

/**
 * Convert a capture direction set to a lower-case string.
 *
 * @param dirs	The direction set to convert.
 *
 * @return The string representing the direction set.
 */
extern const char *kp_cap_dirs_to_lcstr(enum kp_cap_dirs dirs);

/**
 * Convert a capture direction set to a capitalized string.
 *
 * @param dirs	The direction set to convert.
 *
 * @return The string representing the direction set.
 */
extern const char *kp_cap_dirs_to_cpstr(enum kp_cap_dirs dirs);

/** Capture channel configuration */
struct kp_cap_ch_conf {
	/** The movement directions to capture in (bitmap) */
	enum kp_cap_dirs dirs;

	/**
	 * True if the capture should happen on rising edges.
	 * False if it should happen on falling edges.
	 */
	bool rising;

	/** User's channel name */
	char name[KP_CAP_CH_NAME_MAX_LEN + 1];
};

/** Channel capture status */
enum kp_cap_ch_status {
	/** Capture timed out */
	KP_CAP_CH_STATUS_TIMEOUT,
	/** Capture succesfull */
	KP_CAP_CH_STATUS_OK,
	/** More than one capture event occurred */
	KP_CAP_CH_STATUS_OVERCAPTURE,
	/** Number of statuses - not a valid status itself */
	KP_CAP_CH_STATUS_NUM
};

/**
 * Check if a channel status is valid.
 *
 * @param status	The status to check.
 *
 * @return True if the status is valid, false otherwise.
 */
static inline bool
kp_cap_ch_status_is_valid(enum kp_cap_ch_status status)
{
	return status >= 0 && status < KP_CAP_CH_STATUS_NUM;
}

/**
 * Convert a channel's capture status to string.
 *
 * @param status	The status to convert.
 *
 * @return The string representing the status.
 */
extern const char *kp_cap_ch_status_to_str(enum kp_cap_ch_status status);

/** Channel capture result */
struct kp_cap_ch_res {
	/** Capture status */
	enum kp_cap_ch_status status:2;
	/**
	 * Captured time value.
	 * Only valid if status is OK or OVERCAPTURE.
	 */
	uint32_t value_us:30;
};

/**
 * The ISR for UP/CC timer interrupts.
 *
 * @param arg	Unused.
 */
extern void kp_cap_isr(void *arg);


/** Debug output configuration */
struct kp_cap_dbg_conf {
	/*
	 * The GPIO port to use for debug event output.
	 * NULL to have debugging disabled.
	 */
	const struct device *gpio;

	/*
	 * The GPIO pin to use for update interrupt debugging.
	 * Set high at the trigger, set low on update.
	 * Must be configured. Set to UINT8_MAX to disable.
	 */
	gpio_pin_t update_pin;

	/**
	 * The GPIO pins to use for capture interrupt debugging. One per
	 * channel. Each set high at the trigger, set low when the channel is
	 * captured. Each must be configured. Any can be set to UINT8_MAX to
	 * disable.
	 */
	gpio_pin_t cap_pin_list[KP_CAP_CH_NUM];
};

/**
 * Initialize the capturer.
 *
 * @param timer		The STM32 timer to use for capturing.
 * 			The timer's rising CH1 input will be used to start
 * 			counting, and the CH2-CH3 channels to capture events,
 * 			as configured when starting the capture.
 * @param dbg_conf	Debug output configuration.
 *			NULL to have debugging output disabled.
 */
extern void kp_cap_init(TIM_TypeDef* timer,
			const struct kp_cap_dbg_conf *dbg_conf);

/**
 * Check if the capturer is initialized.
 *
 * @return True if the capturer is initialized, false if not.
 */
extern bool kp_cap_is_initialized(void);

/** Capture configuration */
struct kp_cap_conf {
	/** Channel configurations */
	struct kp_cap_ch_conf ch_list[KP_CAP_CH_NUM];
	/**
	 * The maximum time to wait for all channels to be captured,
	 * microseconds. Must not be greater than KP_CAP_TIME_MAX_US -
	 * bounce_us.
	 */
	uint32_t timeout_us;
	/**
	 * The minimum time to wait for a channel to bounce, microseconds.
	 * Must not be greater than KP_CAP_TIME_MAX_US - timeout_us.
	 */
	uint32_t bounce_us;
};

/**
 * Check that a capture configuration is valid.
 *
 * @param conf	The configuration to check.
 *
 * @return True if the configuration is valid, false otherwise.
 */
static inline bool
kp_cap_conf_is_valid(const struct kp_cap_conf *conf)
{
	return conf != NULL &&
	       (conf->timeout_us + conf->bounce_us) <= KP_CAP_TIME_MAX_US;
}

/**
 * Get the number of channels enabled in a configuration for the specified
 * directions.
 *
 * @param conf	The capture configuration to count the channels in.
 * @param dirs	The directions to count the channels in. Use KP_CAP_DIRS_BOTH
 * 		to count all enabled channels, regardless of direction.
 */
extern size_t kp_cap_conf_ch_num(const struct kp_cap_conf *conf,
				 enum kp_cap_dirs dirs);

/**
 * Calculate the index of a channel capture result in a flat result array,
 * for specified configuration, current pass number, the direction of even
 * passes, and the channel number.
 *
 * @param conf		The configuration the capture was done with.
 * @param even_down	True if even passes are directed down, false if up.
 * @param pass		The index of the pass the channel result is in.
 * @param ch		The index of the channel to get index for, within the
 *			pass. Must be less than the number of channels in the
 *			configuration.
 */
extern size_t kp_cap_conf_ch_res_idx(const struct kp_cap_conf *conf,
				     bool even_down,
				     size_t pass,
				     size_t ch);

/**
 * Start capture, waiting for the previous one to finish first.
 *
 * @param conf	Capture configuration to use.
 * @param dirs	The movement directions the capture is happening in.
 */
extern void kp_cap_start(const struct kp_cap_conf *conf, enum kp_cap_dirs dirs);

/**
 * Initialize a poll event to wait for finished captures.
 *
 * @param event	The poll event to initialize.
 */
extern void kp_cap_finish_event_init(struct k_poll_event *event);

/** Capture result code */
enum kp_cap_rc {
	/** Capture succeeded, check individual channel results */
	KP_CAP_RC_OK,
	/** Capture was aborted, channel results not modified */
	KP_CAP_RC_ABORTED,
	/** Waiting for capture timed out, channel results not modified */
	KP_CAP_RC_TIMEOUT,
	/** Number of result codes, not a valid result code itself */
	KP_CAP_RC_NUM
};

/**
 * Check if a capture result code is valid.
 *
 * @param rc	The result code to check.
 *
 * @return True if the result code is valid, false otherwise.
 */
static inline bool
kp_cap_rc_is_valid(enum kp_cap_rc rc)
{
	return rc >= 0 && rc < KP_CAP_RC_NUM;
}

/**
 * Convert a capture result code to string.
 *
 * @param rc	The result code to convert.
 *
 * @return The string representing the result code.
 */
extern const char *kp_cap_rc_to_str(enum kp_cap_rc rc);

/**
 * Abort the current capture, if running.
 *
 * @return True if the capture was running and aborted, false otherwise.
 */
extern bool kp_cap_abort(void);

/**
 * Retrieve capture results when/if they're ready.
 *
 * @param ch_res_list	List of structures for channel capture results.
 * 			Only modified if KP_CAP_RC_OK is returned.
 * 			Only results for channels enabled in the configuration
 * 			and the directions passed to kp_cap_start() (as
 * 			counted by kp_cap_conf_ch_num()) will be output. Can
 * 			be NULL if ch_res_num is zero.
 * @param ch_res_num	Maximum number of channels to retrieve results for.
 * @param timeout	The time to wait for the capture to finish, or one of
 * 			the special values K_NO_WAIT and K_FOREVER.
 *
 * @return The capture result code.
 */
extern enum kp_cap_rc kp_cap_finish(struct kp_cap_ch_res *ch_res_list,
				    size_t ch_res_num, k_timeout_t timeout);

#ifdef __cplusplus
}
#endif

#endif /* KP_CAP_H_ */
```

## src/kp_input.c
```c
/** @file
 *  @brief Keypecker input
 */

/*
 * Copyright (c) 2022 Nikolai Kondrashov
 *
 * SPDX-License-Identifier: GPL-2.0-or-later
 */

#include "kp_input.h"

/** The mutex protecting all the state */
static K_MUTEX_DEFINE(kp_input_mutex);

/** Input message queue */
K_MSGQ_DEFINE(kp_input_msgq, sizeof(enum kp_input_msg),
		16, sizeof(enum kp_input_msg));

/** Input state */
enum kp_input_st {
	/** Base state, no special characters encountered */
	KP_INPUT_ST_NONE,
	/** Escape character encountered */
	KP_INPUT_ST_ESC,
	/** Control Sequence Introducer (CSI) encountered */
	KP_INPUT_ST_CSI,
	/** Control sequence intermediate byte(s) received */
	KP_INPUT_ST_CSI_INT,
};

/** Current input state */
static enum kp_input_st kp_input_st;

void
kp_input_reset(void)
{
	k_mutex_lock(&kp_input_mutex, K_FOREVER);
	kp_input_st = KP_INPUT_ST_NONE;
	k_msgq_purge(&kp_input_msgq);
	k_mutex_unlock(&kp_input_mutex);
}

void
kp_input_recv(uint8_t *data, size_t len)
{
	enum kp_input_msg msg;
	k_mutex_lock(&kp_input_mutex, K_FOREVER);
	for (; len > 0; data++, len--) {
		switch (kp_input_st) {
		/* Base state */
		case KP_INPUT_ST_NONE:
			switch(*data) {
			case 0x03: /* ETX (Ctrl-C) */
				msg = KP_INPUT_MSG_ABORT;
				k_msgq_put(&kp_input_msgq, &msg, K_FOREVER);
				k_mutex_unlock(&kp_input_mutex);
				return;
			case 0x0d: /* CR (Enter) */
				msg = KP_INPUT_MSG_ENTER;
				k_msgq_put(&kp_input_msgq, &msg, K_FOREVER);
				break;
			case 0x1b: /* ESC  */
				kp_input_st = KP_INPUT_ST_ESC;
				break;
			}
			break;
		/* Esc received */
		case KP_INPUT_ST_ESC:
			switch (*data) {
			case '[': /* CSI */
				kp_input_st = KP_INPUT_ST_CSI;
				break;
			default:
				/* Unknown or invalid ESC sequence */
				kp_input_st = KP_INPUT_ST_NONE;
				break;
			}
			break;
		/* If an intermediate byte was received after a CSI */
		case KP_INPUT_ST_CSI_INT:
			/* If a parameter byte is received */
			if ((*data >> 4) == 3) {
				/* Invalid ESC sequence */
				kp_input_st = KP_INPUT_ST_NONE;
				break;
			}
			/* Fallthrough */
		/* CSI has been received */
		case KP_INPUT_ST_CSI:
			switch (*data) {
			case 'A': /* Up arrow */
				msg = KP_INPUT_MSG_UP;
				k_msgq_put(&kp_input_msgq, &msg, K_FOREVER);
				kp_input_st = KP_INPUT_ST_NONE;
				break;
			case 'B': /* Down arrow */
				msg = KP_INPUT_MSG_DOWN;
				k_msgq_put(&kp_input_msgq, &msg, K_FOREVER);
				kp_input_st = KP_INPUT_ST_NONE;
				break;
			default:
				/* If it's an intermediate byte */
				if ((*data >> 4) == 2) {
					kp_input_st = KP_INPUT_ST_CSI_INT;
				/* If it's anything but a parameter byte */
				} else if ((*data >> 4) != 3) {
					/* Finished or invalid ESC sequence */
					kp_input_st = KP_INPUT_ST_NONE;
				}
				break;
			}
			break;
		}

	}
	k_mutex_unlock(&kp_input_mutex);
}

void
kp_input_get_event_init(struct k_poll_event *event)
{
	k_poll_event_init(event, K_POLL_TYPE_MSGQ_DATA_AVAILABLE,
			  K_POLL_MODE_NOTIFY_ONLY, &kp_input_msgq);
}

int
kp_input_get(enum kp_input_msg *msg, k_timeout_t timeout)
{
	return k_msgq_get(&kp_input_msgq, msg, timeout);
}
```

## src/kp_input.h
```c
/** @file
 *  @brief Keypecker input
 */

/*
 * Copyright (c) 2022 Nikolai Kondrashov
 *
 * SPDX-License-Identifier: GPL-2.0-or-later
 */

#ifndef KP_INPUT_H_
#define KP_INPUT_H_

#include <zephyr/kernel.h>

#ifdef __cplusplus
extern "C" {
#endif

/** Input messages */
enum kp_input_msg {
	/** Abort (Ctrl-C) */
	KP_INPUT_MSG_ABORT,
	/** Up arrow */
	KP_INPUT_MSG_UP,
	/** Down arrow */
	KP_INPUT_MSG_DOWN,
	/** Enter */
	KP_INPUT_MSG_ENTER,
};

/**
 * Reset tracked input state to start processing another session.
 */
extern void kp_input_reset(void);

/**
 * Receive raw input for processing.
 *
 * @param data  Raw data from transport.
 * @param len   Data length.
 */
extern void kp_input_recv(uint8_t *data, size_t len);

/**
 * Initialize a poll event to wait for input.
 *
 * @param event	The poll event to initialize.
 */
extern void kp_input_get_event_init(struct k_poll_event *event);

/**
 * Get the next input message.
 *
 * @param msg		Location for the retrieved message.
 * @param timeout	The time to wait for the message to arrive, or one of
 * 			the special values K_NO_WAIT and K_FOREVER.
 *
 * @retval 0 Message received.
 * @retval -ENOMSG Returned without waiting.
 * @retval -EAGAIN Waiting period timed out.
 */
extern int kp_input_get(enum kp_input_msg *msg, k_timeout_t timeout);

#ifdef __cplusplus
}
#endif

#endif /* KP_INPUT_H_ */
```

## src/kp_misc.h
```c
/** @file
 *  @brief Keypecker - miscellaneous definitions
 */

/*
 * Copyright (c) 2023 Nikolai Kondrashov
 *
 * SPDX-License-Identifier: GPL-2.0-or-later
 */

#ifndef KP_MISC_H_
#define KP_MISC_H_

#include <zephyr/sys/util.h>
#include <strings.h>
#include <string.h>

#ifdef __cplusplus
extern "C" {
#endif

static inline int
kp_strcasecmp(const char *a, const char *b)
{
	return strncasecmp(a, b, MAX(strlen(a), strlen(b)));
}

#ifdef __cplusplus
}
#endif

#endif /* KP_MISC_H_ */
```
